VERSION ""

NS_ :

BS_:

BU_: Host Bootloader Application

BO_ 1792 Bootloader_TX: 8 Bootloader
 SG_ ResponseType : 0|8@1+ (1,0) [0|255] ""  Host
 SG_ ErrorCode : 8|8@1+ (1,0) [0|255] ""  Host
 SG_ State : 16|8@1+ (1,0) [0|255] ""  Host
 SG_ BytesWritten : 24|32@1+ (1,0) [0|4294967295] "bytes"  Host
 SG_ CRC32_Value : 0|32@1+ (1,0) [0|4294967295] ""  Host

CM_ SG_ 1792 ResponseType "Bootloader response type";
CM_ SG_ 1792 ErrorCode "Error code (0=no error)";
CM_ SG_ 1792 State "Bootloader state machine state";
CM_ SG_ 1792 BytesWritten "Total bytes written to flash";
CM_ SG_ 1792 CRC32_Value "CRC32 checksum value (for RESP_CRC)";

VAL_ 1792 ResponseType 16 "ACK" 17 "NACK" 18 "ERROR" 19 "BUSY" 20 "READY" 21 "DATA" 22 "CRC_RESPONSE" ;
VAL_ 1792 ErrorCode 0 "ERR_NONE" 1 "ERR_INVALID_COMMAND" 2 "ERR_INVALID_ADDRESS" 3 "ERR_FLASH_ERASE_FAILED" 4 "ERR_FLASH_WRITE_FAILED" 5 "ERR_INVALID_DATA_LENGTH" 6 "ERR_NO_VALID_APP" 7 "ERR_TIMEOUT" ;
VAL_ 1792 State 0 "IDLE" 1 "ERASING" 2 "WRITING" 3 "READING" 4 "VERIFYING" 5 "JUMPING" ;

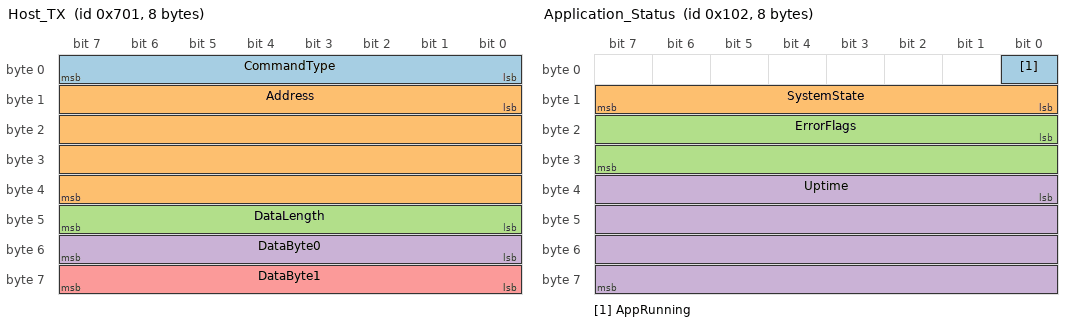
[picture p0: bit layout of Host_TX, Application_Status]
BO_ 1793 Host_TX: 8 Host
 SG_ CommandType : 0|8@1+ (1,0) [0|255] ""  Bootloader
 SG_ Address : 8|32@1+ (1,0) [0|4294967295] ""  Bootloader
 SG_ DataLength : 40|8@1+ (1,0) [0|255] "bytes"  Bootloader
 SG_ DataByte0 : 48|8@1+ (1,0) [0|255] ""  Bootloader
 SG_ DataByte1 : 56|8@1+ (1,0) [0|255] ""  Bootloader

CM_ SG_ 1793 CommandType "Host command to bootloader";
CM_ SG_ 1793 Address "Flash memory address for read/write/set operations";
CM_ SG_ 1793 DataLength "Number of bytes to read or write";
CM_ SG_ 1793 DataByte0 "First data byte (for write operations)";
CM_ SG_ 1793 DataByte1 "Second data byte (for write operations)";

VAL_ 1793 CommandType 1 "CMD_ERASE_FLASH" 2 "CMD_WRITE_FLASH" 3 "CMD_READ_FLASH" 4 "CMD_JUMP_TO_APP" 5 "CMD_GET_STATUS" 6 "CMD_SET_ADDRESS" 7 "CMD_WRITE_DATA" ;

BO_ 258 Application_Status: 8 Application
 SG_ AppRunning : 0|1@1+ (1,0) [0|1] ""  Host
 SG_ SystemState : 8|8@1+ (1,0) [0|255] ""  Host
 SG_ ErrorFlags : 16|16@1+ (1,0) [0|65535] ""  Host
 SG_ Uptime : 32|32@1+ (1,0) [0|4294967295] "seconds"  Host

CM_ SG_ 258 AppRunning "Application running flag";
CM_ SG_ 258 SystemState "Current system state";
CM_ SG_ 258 ErrorFlags "Error flag bits";
CM_ SG_ 258 Uptime "System uptime in seconds";

VAL_ 258 AppRunning 0 "Stopped" 1 "Running" ;
VAL_ 258 SystemState 0 "Init" 1 "Normal" 2 "Error" 3 "Shutdown" ;
